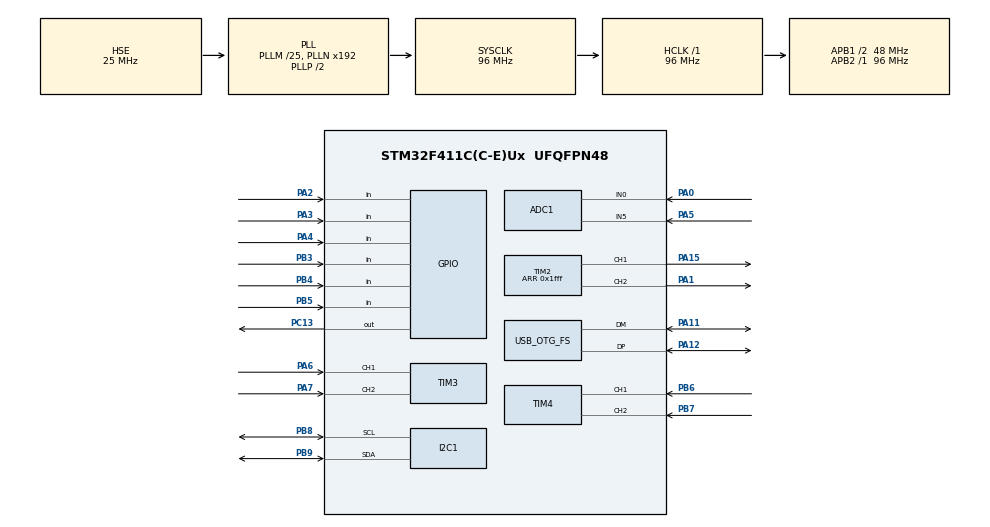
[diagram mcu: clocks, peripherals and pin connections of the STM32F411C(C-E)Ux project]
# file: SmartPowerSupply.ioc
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ADC1.Channel-0\#ChannelRegularConversion=ADC_CHANNEL_0
ADC1.Channel-1\#ChannelInjectedConversion=ADC_CHANNEL_VREFINT
ADC1.Channel-2\#ChannelInjectedConversion=ADC_CHANNEL_0
ADC1.Channel-3\#ChannelInjectedConversion=ADC_CHANNEL_5
ADC1.Channel-4\#ChannelInjectedConversion=ADC_CHANNEL_0
ADC1.ClockPrescaler=ADC_CLOCK_SYNC_PCLK_DIV4
ADC1.ContinuousConvMode=ENABLE
ADC1.EOCSelection=ADC_EOC_SEQ_CONV
ADC1.InjNumberOfConversion=4
ADC1.InjectedConvMode=AutoInjected
ADC1.InjectedOffset-1\#ChannelInjectedConversion=0
ADC1.InjectedOffset-2\#ChannelInjectedConversion=0
ADC1.InjectedOffset-3\#ChannelInjectedConversion=0
ADC1.InjectedOffset-4\#ChannelInjectedConversion=0
ADC1.InjectedRank-1\#ChannelInjectedConversion=1
ADC1.InjectedRank-2\#ChannelInjectedConversion=2
ADC1.InjectedRank-3\#ChannelInjectedConversion=3
ADC1.InjectedRank-4\#ChannelInjectedConversion=4
ADC1.NbrOfConversionFlag=1
ADC1.Rank-0\#ChannelRegularConversion=1
ADC1.SamplingTime-0\#ChannelRegularConversion=ADC_SAMPLETIME_28CYCLES
ADC1.SamplingTime-1\#ChannelInjectedConversion=ADC_SAMPLETIME_56CYCLES
ADC1.SamplingTime-2\#ChannelInjectedConversion=ADC_SAMPLETIME_56CYCLES
ADC1.SamplingTime-3\#ChannelInjectedConversion=ADC_SAMPLETIME_56CYCLES
ADC1.SamplingTime-4\#ChannelInjectedConversion=ADC_SAMPLETIME_3CYCLES
ADC1.ScanConvMode=ENABLE
ADC1.master=1
FREERTOS.Tasks01=defaultTask,24,512,StartDefaultTask,Default,NULL,Dynamic,NULL,NULL;render,24,512,renderer,Default,NULL,Dynamic,NULL,NULL
FREERTOS.configENABLE_FPU=1
FREERTOS.configUSE_NEWLIB_REENTRANT=1
Mcu.Family=STM32F4
Mcu.Name=STM32F411C(C-E)Ux
Mcu.Package=UFQFPN48
NVIC.OTG_FS_IRQn=true\:5\:0\:false\:false\:true\:true\:false\:true\:true
NVIC.PriorityGroup=NVIC_PRIORITYGROUP_4
NVIC.TIM1_TRG_COM_TIM11_IRQn=true\:15\:0\:false\:false\:true\:false\:false\:true\:true
NVIC.TimeBase=TIM1_TRG_COM_TIM11_IRQn
NVIC.TimeBaseIP=TIM11
PA0-WKUP.Signal=ADCx_IN0
PA1.GPIO_Speed=GPIO_SPEED_FREQ_VERY_HIGH
PA1.Signal=S_TIM2_CH2
PA11.Mode=Device_Only
PA11.Signal=USB_OTG_FS_DM
PA12.Mode=Device_Only
PA12.Signal=USB_OTG_FS_DP
PA13.Mode=Serial_Wire
PA13.Signal=SYS_JTMS-SWDIO
PA14.Mode=Serial_Wire
PA14.Signal=SYS_JTCK-SWCLK
PA15.GPIO_Speed=GPIO_SPEED_FREQ_VERY_HIGH
PA15.Signal=S_TIM2_CH1_ETR
PA2.Signal=GPIO_Input
PA3.GPIO_PuPd=GPIO_PULLUP
PA3.Signal=GPIO_Input
PA4.GPIO_PuPd=GPIO_PULLUP
PA4.Signal=GPIO_Input
PA5.Signal=ADCx_IN5
PA6.GPIO_PuPd=GPIO_PULLUP
PA6.Signal=S_TIM3_CH1
PA7.GPIO_PuPd=GPIO_PULLUP
PA7.Signal=S_TIM3_CH2
PB3.GPIO_PuPd=GPIO_PULLUP
PB3.Signal=GPIO_Input
PB4.GPIO_PuPd=GPIO_PULLUP
PB4.Signal=GPIO_Input
PB5.GPIO_PuPd=GPIO_PULLDOWN
PB5.Signal=GPIO_Input
PB6.GPIO_PuPd=GPIO_PULLUP
PB6.Signal=S_TIM4_CH1
PB7.GPIO_PuPd=GPIO_PULLUP
PB7.Signal=S_TIM4_CH2
PB8.Mode=I2C
PB8.Signal=I2C1_SCL
PB9.Mode=I2C
PB9.Signal=I2C1_SDA
PC13-ANTI_TAMP.Signal=GPIO_Output
PH0\ -\ OSC_IN.Mode=HSE-External-Oscillator
PH0\ -\ OSC_IN.Signal=RCC_OSC_IN
PH1\ -\ OSC_OUT.Mode=HSE-External-Oscillator
PH1\ -\ OSC_OUT.Signal=RCC_OSC_OUT
ProjectManager.HeapSize=0x200
ProjectManager.StackSize=0x400
ProjectManager.TargetToolchain=STM32CubeIDE
RCC.48MHZClocksFreq_Value=48000000
RCC.AHBFreq_Value=96000000
RCC.APB1CLKDivider=RCC_HCLK_DIV2
RCC.APB1Freq_Value=48000000
RCC.APB1TimFreq_Value=96000000
RCC.APB2Freq_Value=96000000
RCC.APB2TimFreq_Value=96000000
RCC.CortexFreq_Value=96000000
RCC.HCLKFreq_Value=96000000
RCC.HSE_VALUE=25000000
RCC.HSI_VALUE=16000000
RCC.LSE_VALUE=32768
RCC.PLLM=25
RCC.SYSCLKFreq_VALUE=96000000
RCC.SYSCLKSource=RCC_SYSCLKSOURCE_PLLCLK
RCC.VCOOutputFreq_Value=192000000
SH.ADCx_IN0.0=ADC1_IN0,IN0
SH.ADCx_IN5.0=ADC1_IN5,IN5
SH.S_TIM2_CH1_ETR.0=TIM2_CH1,PWM Generation1 CH1
SH.S_TIM2_CH2.0=TIM2_CH2,PWM Generation2 CH2
SH.S_TIM3_CH1.0=TIM3_CH1,Encoder_Interface
SH.S_TIM3_CH2.0=TIM3_CH2,Encoder_Interface
SH.S_TIM4_CH1.0=TIM4_CH1,Encoder_Interface
SH.S_TIM4_CH2.0=TIM4_CH2,Encoder_Interface
TIM2.AutoReloadPreload=TIM_AUTORELOAD_PRELOAD_ENABLE
TIM2.Channel-PWM\ Generation1\ CH1=TIM_CHANNEL_1
TIM2.Channel-PWM\ Generation2\ CH2=TIM_CHANNEL_2
TIM2.Period=0x1fff
TIM3.AutoReloadPreload=TIM_AUTORELOAD_PRELOAD_ENABLE
TIM3.CounterMode=TIM_COUNTERMODE_UP
TIM3.EncoderMode=TIM_ENCODERMODE_TI12
TIM3.IC1Filter=15
TIM3.IC1Polarity=TIM_ICPOLARITY_FALLING
TIM3.IC2Filter=15
TIM4.AutoReloadPreload=TIM_AUTORELOAD_PRELOAD_ENABLE
TIM4.EncoderMode=TIM_ENCODERMODE_TI12
TIM4.IC1Filter=10
TIM4.IC1Polarity=TIM_ICPOLARITY_RISING
USB_DEVICE.CLASS_NAME_FS=CDC
USB_DEVICE.USBD_DEBUG_LEVEL=2
USB_DEVICE.VirtualMode=Cdc
USB_DEVICE.VirtualModeFS=Cdc_FS
USB_OTG_FS.VirtualMode=Device_Only
VP_ADC1_Vref_Input.Mode=IN-Vrefint
VP_FREERTOS_VS_CMSIS_V2.Mode=CMSIS_V2
VP_SYS_VS_tim11.Mode=TIM11
VP_TIM10_VS_ClockSourceINT.Mode=Enable_Timer
VP_TIM2_VS_ClockSourceINT.Mode=Internal
VP_USB_DEVICE_VS_USB_DEVICE_CDC_FS.Mode=CDC_FS
board=custom

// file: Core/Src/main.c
/* USER CODE BEGIN Header */
/**
  ******************************************************************************
  * @file           : main.c
  * @brief          : Main program body
  ******************************************************************************
  * @attention
  *
  * Copyright (c) 2024 STMicroelectronics.
  * All rights reserved.
  *
  * This software is licensed under terms that can be found in the LICENSE file
  * in the root directory of this software component.
  * If no LICENSE file comes with this software, it is provided AS-IS.
  *
  ******************************************************************************
  */
/* USER CODE END Header */
#include "main.h"
#include "cmsis_os.h"
#include "usb_device.h"

/* USER CODE BEGIN Includes */
#include "App/App/app.h"
#include "App/HwInit/hwinit.h"
/* USER CODE END Includes */

/* USER CODE BEGIN PM */

// htim1;
// htim2;  encoder 2
// pwm;  2 chanel pwm
// htim4;  encoder 1
// htim10; for micro delays
/* USER CODE END PM */

ADC_HandleTypeDef hadc1;

I2C_HandleTypeDef hi2c1;

TIM_HandleTypeDef htim2;
TIM_HandleTypeDef htim3;
TIM_HandleTypeDef htim4;
TIM_HandleTypeDef htim10;

/* Definitions for defaultTask */
osThreadId_t defaultTaskHandle;
const osThreadAttr_t defaultTask_attributes = {
  .name = "defaultTask",
  .stack_size = 512 * 4,
  .priority = (osPriority_t) osPriorityNormal,
};
/* Definitions for render */
osThreadId_t renderHandle;
const osThreadAttr_t render_attributes = {
  .name = "render",
  .stack_size = 512 * 4,
  .priority = (osPriority_t) osPriorityNormal,
};

void SystemClock_Config(void);
static void MX_GPIO_Init(void);
static void MX_ADC1_Init(void);
static void MX_I2C1_Init(void);
static void MX_TIM3_Init(void);
static void MX_TIM4_Init(void);
static void MX_TIM2_Init(void);
static void MX_TIM10_Init(void);
void StartDefaultTask(void *argument);
void renderer(void *argument);

int main(void)
{

  /* MCU Configuration--------------------------------------------------------*/

  /* Reset of all peripherals, Initializes the Flash interface and the Systick. */
  HAL_Init();

  /* Configure the system clock */
  SystemClock_Config();

  /* Initialize all configured peripherals */
  MX_GPIO_Init();
  MX_ADC1_Init();
  MX_I2C1_Init();
  MX_TIM3_Init();
  MX_TIM4_Init();
  MX_TIM2_Init();
  MX_TIM10_Init();
  /* USER CODE BEGIN 2 */
    //start timers

    // htim1;
    // htim2;  2 chanel pwm
    // htim3;  encoder 1
    // htim4;  encoder 2
    // htim10; for micro delays
    hwInit(&hadc1, &hi2c1, &htim2, &htim3, &htim4, &htim10);
  /* USER CODE END 2 */

  /* Init scheduler */
  osKernelInitialize();

  /* Create the thread(s) */
  /* creation of defaultTask */
  defaultTaskHandle = osThreadNew(StartDefaultTask, NULL, &defaultTask_attributes);

  /* creation of render */
  renderHandle = osThreadNew(renderer, NULL, &render_attributes);

  /* Start scheduler */
  osKernelStart();

  /* We should never get here as control is now taken by the scheduler */

  /* Infinite loop */
    while (1) {

    }
}

void SystemClock_Config(void)
{
  RCC_OscInitTypeDef RCC_OscInitStruct = {0};
  RCC_ClkInitTypeDef RCC_ClkInitStruct = {0};

  /** Configure the main internal regulator output voltage
  */
  __HAL_RCC_PWR_CLK_ENABLE();
  __HAL_PWR_VOLTAGESCALING_CONFIG(PWR_REGULATOR_VOLTAGE_SCALE1);

  /** Initializes the RCC Oscillators according to the specified parameters
  * in the RCC_OscInitTypeDef structure.
  */
  RCC_OscInitStruct.OscillatorType = RCC_OSCILLATORTYPE_HSE;
  RCC_OscInitStruct.HSEState = RCC_HSE_ON;
  RCC_OscInitStruct.PLL.PLLState = RCC_PLL_ON;
  RCC_OscInitStruct.PLL.PLLSource = RCC_PLLSOURCE_HSE;
  RCC_OscInitStruct.PLL.PLLM = 25;
  RCC_OscInitStruct.PLL.PLLN = 192;
  RCC_OscInitStruct.PLL.PLLP = RCC_PLLP_DIV2;
  RCC_OscInitStruct.PLL.PLLQ = 4;
  if (HAL_RCC_OscConfig(&RCC_OscInitStruct) != HAL_OK)
  {
    Error_Handler();
  }

  /** Initializes the CPU, AHB and APB buses clocks
  */
  RCC_ClkInitStruct.ClockType = RCC_CLOCKTYPE_HCLK|RCC_CLOCKTYPE_SYSCLK
                              |RCC_CLOCKTYPE_PCLK1|RCC_CLOCKTYPE_PCLK2;
  RCC_ClkInitStruct.SYSCLKSource = RCC_SYSCLKSOURCE_PLLCLK;
  RCC_ClkInitStruct.AHBCLKDivider = RCC_SYSCLK_DIV1;
  RCC_ClkInitStruct.APB1CLKDivider = RCC_HCLK_DIV2;
  RCC_ClkInitStruct.APB2CLKDivider = RCC_HCLK_DIV1;

  if (HAL_RCC_ClockConfig(&RCC_ClkInitStruct, FLASH_LATENCY_3) != HAL_OK)
  {
    Error_Handler();
  }
}

static void MX_ADC1_Init(void)
{

  ADC_ChannelConfTypeDef sConfig = {0};
  ADC_InjectionConfTypeDef sConfigInjected = {0};

  /** Configure the global features of the ADC (Clock, Resolution, Data Alignment and number of conversion)
  */
  hadc1.Instance = ADC1;
  hadc1.Init.ClockPrescaler = ADC_CLOCK_SYNC_PCLK_DIV4;
  hadc1.Init.Resolution = ADC_RESOLUTION_12B;
  hadc1.Init.ScanConvMode = ENABLE;
  hadc1.Init.ContinuousConvMode = ENABLE;
  hadc1.Init.DiscontinuousConvMode = DISABLE;
  hadc1.Init.ExternalTrigConvEdge = ADC_EXTERNALTRIGCONVEDGE_NONE;
  hadc1.Init.ExternalTrigConv = ADC_SOFTWARE_START;
  hadc1.Init.DataAlign = ADC_DATAALIGN_RIGHT;
  hadc1.Init.NbrOfConversion = 1;
  hadc1.Init.DMAContinuousRequests = DISABLE;
  hadc1.Init.EOCSelection = ADC_EOC_SEQ_CONV;
  if (HAL_ADC_Init(&hadc1) != HAL_OK)
  {
    Error_Handler();
  }

  /** Configure for the selected ADC regular channel its corresponding rank in the sequencer and its sample time.
  */
  sConfig.Channel = ADC_CHANNEL_0;
  sConfig.Rank = 1;
  sConfig.SamplingTime = ADC_SAMPLETIME_28CYCLES;
  if (HAL_ADC_ConfigChannel(&hadc1, &sConfig) != HAL_OK)
  {
    Error_Handler();
  }

  /** Configures for the selected ADC injected channel its corresponding rank in the sequencer and its sample time
  */
  sConfigInjected.InjectedChannel = ADC_CHANNEL_VREFINT;
  sConfigInjected.InjectedRank = 1;
  sConfigInjected.InjectedNbrOfConversion = 4;
  sConfigInjected.InjectedSamplingTime = ADC_SAMPLETIME_56CYCLES;
  sConfigInjected.ExternalTrigInjecConvEdge = ADC_EXTERNALTRIGINJECCONVEDGE_NONE;
  sConfigInjected.ExternalTrigInjecConv = ADC_INJECTED_SOFTWARE_START;
  sConfigInjected.AutoInjectedConv = ENABLE;
  sConfigInjected.InjectedDiscontinuousConvMode = DISABLE;
  sConfigInjected.InjectedOffset = 0;
  if (HAL_ADCEx_InjectedConfigChannel(&hadc1, &sConfigInjected) != HAL_OK)
  {
    Error_Handler();
  }

  /** Configures for the selected ADC injected channel its corresponding rank in the sequencer and its sample time
  */
  sConfigInjected.InjectedChannel = ADC_CHANNEL_0;
  sConfigInjected.InjectedRank = 2;
  if (HAL_ADCEx_InjectedConfigChannel(&hadc1, &sConfigInjected) != HAL_OK)
  {
    Error_Handler();
  }

  /** Configures for the selected ADC injected channel its corresponding rank in the sequencer and its sample time
  */
  sConfigInjected.InjectedChannel = ADC_CHANNEL_5;
  sConfigInjected.InjectedRank = 3;
  if (HAL_ADCEx_InjectedConfigChannel(&hadc1, &sConfigInjected) != HAL_OK)
  {
    Error_Handler();
  }

  /** Configures for the selected ADC injected channel its corresponding rank in the sequencer and its sample time
  */
  sConfigInjected.InjectedChannel = ADC_CHANNEL_0;
  sConfigInjected.InjectedRank = 4;
  sConfigInjected.InjectedSamplingTime = ADC_SAMPLETIME_3CYCLES;
  if (HAL_ADCEx_InjectedConfigChannel(&hadc1, &sConfigInjected) != HAL_OK)
  {
    Error_Handler();
  }

}

static void MX_I2C1_Init(void)
{

  hi2c1.Instance = I2C1;
  hi2c1.Init.ClockSpeed = 100000;
  hi2c1.Init.DutyCycle = I2C_DUTYCYCLE_2;
  hi2c1.Init.OwnAddress1 = 0;
  hi2c1.Init.AddressingMode = I2C_ADDRESSINGMODE_7BIT;
  hi2c1.Init.DualAddressMode = I2C_DUALADDRESS_DISABLE;
  hi2c1.Init.OwnAddress2 = 0;
  hi2c1.Init.GeneralCallMode = I2C_GENERALCALL_DISABLE;
  hi2c1.Init.NoStretchMode = I2C_NOSTRETCH_DISABLE;
  if (HAL_I2C_Init(&hi2c1) != HAL_OK)
  {
    Error_Handler();
  }

}

static void MX_TIM2_Init(void)
{

  TIM_ClockConfigTypeDef sClockSourceConfig = {0};
  TIM_MasterConfigTypeDef sMasterConfig = {0};
  TIM_OC_InitTypeDef sConfigOC = {0};

  htim2.Instance = TIM2;
  htim2.Init.Prescaler = 0;
  htim2.Init.CounterMode = TIM_COUNTERMODE_UP;
  htim2.Init.Period = 0x1fff;
  htim2.Init.ClockDivision = TIM_CLOCKDIVISION_DIV1;
  htim2.Init.AutoReloadPreload = TIM_AUTORELOAD_PRELOAD_ENABLE;
  if (HAL_TIM_Base_Init(&htim2) != HAL_OK)
  {
    Error_Handler();
  }
  sClockSourceConfig.ClockSource = TIM_CLOCKSOURCE_INTERNAL;
  if (HAL_TIM_ConfigClockSource(&htim2, &sClockSourceConfig) != HAL_OK)
  {
    Error_Handler();
  }
  if (HAL_TIM_PWM_Init(&htim2) != HAL_OK)
  {
    Error_Handler();
  }
  sMasterConfig.MasterOutputTrigger = TIM_TRGO_RESET;
  sMasterConfig.MasterSlaveMode = TIM_MASTERSLAVEMODE_DISABLE;
  if (HAL_TIMEx_MasterConfigSynchronization(&htim2, &sMasterConfig) != HAL_OK)
  {
    Error_Handler();
  }
  sConfigOC.OCMode = TIM_OCMODE_PWM1;
  sConfigOC.Pulse = 0;
  sConfigOC.OCPolarity = TIM_OCPOLARITY_HIGH;
  sConfigOC.OCFastMode = TIM_OCFAST_DISABLE;
  if (HAL_TIM_PWM_ConfigChannel(&htim2, &sConfigOC, TIM_CHANNEL_1) != HAL_OK)
  {
    Error_Handler();
  }
  if (HAL_TIM_PWM_ConfigChannel(&htim2, &sConfigOC, TIM_CHANNEL_2) != HAL_OK)
  {
    Error_Handler();
  }
  HAL_TIM_MspPostInit(&htim2);

}

static void MX_TIM3_Init(void)
{

  TIM_Encoder_InitTypeDef sConfig = {0};
  TIM_MasterConfigTypeDef sMasterConfig = {0};

  htim3.Instance = TIM3;
  htim3.Init.Prescaler = 0;
  htim3.Init.CounterMode = TIM_COUNTERMODE_UP;
  htim3.Init.Period = 65535;
  htim3.Init.ClockDivision = TIM_CLOCKDIVISION_DIV1;
  htim3.Init.AutoReloadPreload = TIM_AUTORELOAD_PRELOAD_ENABLE;
  sConfig.EncoderMode = TIM_ENCODERMODE_TI12;
  sConfig.IC1Polarity = TIM_ICPOLARITY_FALLING;
  sConfig.IC1Selection = TIM_ICSELECTION_DIRECTTI;
  sConfig.IC1Prescaler = TIM_ICPSC_DIV1;
  sConfig.IC1Filter = 15;
  sConfig.IC2Polarity = TIM_ICPOLARITY_RISING;
  sConfig.IC2Selection = TIM_ICSELECTION_DIRECTTI;
  sConfig.IC2Prescaler = TIM_ICPSC_DIV1;
  sConfig.IC2Filter = 15;
  if (HAL_TIM_Encoder_Init(&htim3, &sConfig) != HAL_OK)
  {
    Error_Handler();
  }
  sMasterConfig.MasterOutputTrigger = TIM_TRGO_RESET;
  sMasterConfig.MasterSlaveMode = TIM_MASTERSLAVEMODE_DISABLE;
  if (HAL_TIMEx_MasterConfigSynchronization(&htim3, &sMasterConfig) != HAL_OK)
  {
    Error_Handler();
  }

}

static void MX_TIM4_Init(void)
{

  TIM_Encoder_InitTypeDef sConfig = {0};
  TIM_MasterConfigTypeDef sMasterConfig = {0};

  htim4.Instance = TIM4;
  htim4.Init.Prescaler = 0;
  htim4.Init.CounterMode = TIM_COUNTERMODE_UP;
  htim4.Init.Period = 65535;
  htim4.Init.ClockDivision = TIM_CLOCKDIVISION_DIV1;
  htim4.Init.AutoReloadPreload = TIM_AUTORELOAD_PRELOAD_ENABLE;
  sConfig.EncoderMode = TIM_ENCODERMODE_TI12;
  sConfig.IC1Polarity = TIM_ICPOLARITY_RISING;
  sConfig.IC1Selection = TIM_ICSELECTION_DIRECTTI;
  sConfig.IC1Prescaler = TIM_ICPSC_DIV1;
  sConfig.IC1Filter = 10;
  sConfig.IC2Polarity = TIM_ICPOLARITY_RISING;
  sConfig.IC2Selection = TIM_ICSELECTION_DIRECTTI;
  sConfig.IC2Prescaler = TIM_ICPSC_DIV1;
  sConfig.IC2Filter = 0;
  if (HAL_TIM_Encoder_Init(&htim4, &sConfig) != HAL_OK)
  {
    Error_Handler();
  }
  sMasterConfig.MasterOutputTrigger = TIM_TRGO_RESET;
  sMasterConfig.MasterSlaveMode = TIM_MASTERSLAVEMODE_DISABLE;
  if (HAL_TIMEx_MasterConfigSynchronization(&htim4, &sMasterConfig) != HAL_OK)
  {
    Error_Handler();
  }

}

static void MX_TIM10_Init(void)
{

  htim10.Instance = TIM10;
  htim10.Init.Prescaler = 0;
  htim10.Init.CounterMode = TIM_COUNTERMODE_UP;
  htim10.Init.Period = 65535;
  htim10.Init.ClockDivision = TIM_CLOCKDIVISION_DIV1;
  htim10.Init.AutoReloadPreload = TIM_AUTORELOAD_PRELOAD_DISABLE;
  if (HAL_TIM_Base_Init(&htim10) != HAL_OK)
  {
    Error_Handler();
  }

}

static void MX_GPIO_Init(void)
{
  GPIO_InitTypeDef GPIO_InitStruct = {0};

  /* GPIO Ports Clock Enable */
  __HAL_RCC_GPIOC_CLK_ENABLE();
  __HAL_RCC_GPIOH_CLK_ENABLE();
  __HAL_RCC_GPIOA_CLK_ENABLE();
  __HAL_RCC_GPIOB_CLK_ENABLE();

  /*Configure GPIO pin Output Level */
  HAL_GPIO_WritePin(GPIOC, GPIO_PIN_13, GPIO_PIN_RESET);

  /*Configure GPIO pin : PC13 */
  GPIO_InitStruct.Pin = GPIO_PIN_13;
  GPIO_InitStruct.Mode = GPIO_MODE_OUTPUT_PP;
  GPIO_InitStruct.Pull = GPIO_NOPULL;
  GPIO_InitStruct.Speed = GPIO_SPEED_FREQ_LOW;
  HAL_GPIO_Init(GPIOC, &GPIO_InitStruct);

  /*Configure GPIO pin : PA2 */
  GPIO_InitStruct.Pin = GPIO_PIN_2;
  GPIO_InitStruct.Mode = GPIO_MODE_INPUT;
  GPIO_InitStruct.Pull = GPIO_NOPULL;
  HAL_GPIO_Init(GPIOA, &GPIO_InitStruct);

  /*Configure GPIO pins : PA3 PA4 */
  GPIO_InitStruct.Pin = GPIO_PIN_3|GPIO_PIN_4;
  GPIO_InitStruct.Mode = GPIO_MODE_INPUT;
  GPIO_InitStruct.Pull = GPIO_PULLUP;
  HAL_GPIO_Init(GPIOA, &GPIO_InitStruct);

  /*Configure GPIO pins : PB3 PB4 */
  GPIO_InitStruct.Pin = GPIO_PIN_3|GPIO_PIN_4;
  GPIO_InitStruct.Mode = GPIO_MODE_INPUT;
  GPIO_InitStruct.Pull = GPIO_PULLUP;
  HAL_GPIO_Init(GPIOB, &GPIO_InitStruct);

  /*Configure GPIO pin : PB5 */
  GPIO_InitStruct.Pin = GPIO_PIN_5;
  GPIO_InitStruct.Mode = GPIO_MODE_INPUT;
  GPIO_InitStruct.Pull = GPIO_PULLDOWN;
  HAL_GPIO_Init(GPIOB, &GPIO_InitStruct);

}

void StartDefaultTask(void *argument)
{
  /* init code for USB_DEVICE */
  MX_USB_DEVICE_Init();
  /* USER CODE BEGIN 5 */
    app();
  /* USER CODE END 5 */
}

void renderer(void *argument)
{
  /* USER CODE BEGIN renderer */
    render();
  /* USER CODE END renderer */
}

void HAL_TIM_PeriodElapsedCallback(TIM_HandleTypeDef *htim)
{
  if (htim->Instance == TIM11) {
    HAL_IncTick();
  }
}

void Error_Handler(void)
{
    __disable_irq();
    while (1) {
    }
}
